# M051DN_v1 register map
File version: 1.0
Registers are 32-bit, read-write, reset 0x0 unless marked. A register's access mark holds for its fields unless they carry their own. Offsets are from the block's base; [hi:lo] are bit positions; 'fields as' and 'values as' point back to an identical list.

## TMR01 — TIMER Register Map
Base 0x40010000
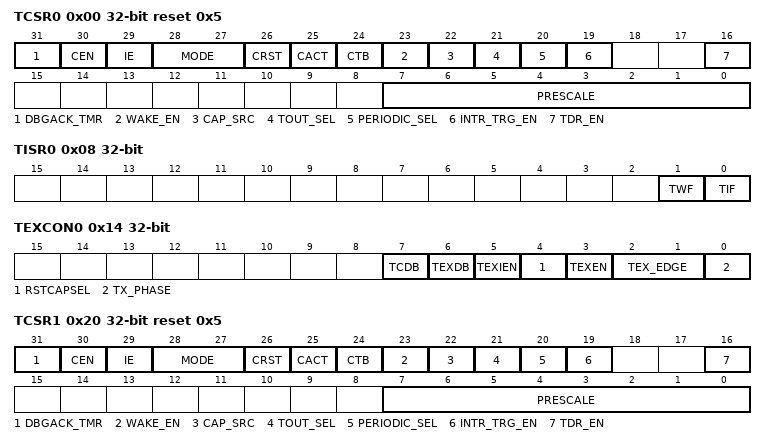
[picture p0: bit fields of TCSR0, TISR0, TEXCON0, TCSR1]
0x00 TCSR0 reset 0x5 — Timer0 Control and Status Register
  [31] DBGACK_TMR — ICE Debug Mode Acknowledge Disable (Write Protect). Timer counter will keep going no matter CPU is held by ICE or not.
    0=ICE debug mode acknowledgement effects TIMER counting; 1=ICE debug mode acknowledgement Disabled
  [30] CEN — Timer Enable Control
    0=Stops/Suspends counting; 1=Starts counting
  [29] IE — Interrupt Enable Control. If this bit is enabled, when the timer interrupt flag (TIF) is set to 1, the timer interrupt signal is generated and inform to CPU.
    0=Timer Interrupt function Disabled; 1=Timer Interrupt function Enabled
  [28:27] MODE — Timer Operating Mode
    0=The Timer controller is operated in One-shot mode; 1=The Timer controller is operated in Periodic mode; 2=The Timer controller is operated in Toggle-output mode; 3=The Timer controller is operated in Continuous Counting mode
  [26] CRST — Timer Reset
    0=No effect; 1=Reset 8-bit prescale counter, 24-bit up counter value and CEN bit if CACT is 1
  [25] CACT ro — Timer Active Status (Read Only). This bit indicates the 24-bit up counter status.
    0=24-bit up counter is not active; 1=24-bit up counter is active
  [24] CTB — Counter Mode Enable Control. This bit is for external counting pin function enabled. When timer is used as an event counter, this bit should be set to 1 and select HCLK as timer clock source. Please refer to section 6.7.5.3 for detail description.
    0=External event counter mode Disabled; 1=External event counter mode Enabled
  [23] WAKE_EN — Wake-up Function Enable Control (M05xxDN/DE Only)
    0=Wake-up trigger event Disabled; 1=Wake-up trigger event Enabled
  [22] CAP_SRC — Capture Pin Source Selection (M05xxDN/DE Only)
    0=Capture Function source is from TxEX pin; 1=Capture Function source is from internal ACMPx output signal
  [21] TOUT_SEL — Toggle-output Pin Selection (M05xxDN/DE Only)
    0=Toggle-output pin is from Tx pin; 1=Toggle-output pin is from TxEx pin
  [20] PERIODIC_SEL — Periodic Mode Behavior Selection Enable (M05xxDN/DE Only). If updated TCMP value TDR, TDR will be reset to default value.
    0=The behavior selection in periodic mode is Disabled; 1=The behavior selection in periodic mode is Enabled
  [19] INTR_TRG_EN — Inter-timer Trigger Mode Enable Control (M05xxDN/DE Only). Setting this bit will enable the inter-timer trigger capture function. The Timer0/2 will be in counter mode and counting with external clock source or event.Also, Timer1/3 will be in trigger-counting mode of capture function. Note: For Timer1/3, this bit is ignored and the read back value is always 0.
    0=Inter-Timer Trigger Capture mode Disabled; 1=Inter-Timer Trigger Capture mode Enabled
  [16] TDR_EN — Data Load Enable Control. When TDR_EN is set, TDR (Timer Data Register) will be updated continuously with the 24-bit up-timer value as the timer is counting.
    0=Timer Data Register update Disabled; 1=Timer Data Register update Enabled while Timer counter is active
  [7:0] PRESCALE — Prescale Counter
0x04 TCMPR0 — Timer0 Compare Register
  [23:0] TCMP — Timer Compared Value. TCMP is a 24-bit compared value register. When the internal 24-bit up counter value is equal to TCMP value, the TIF flag will set to 1. Note1: Never write 0x0 or 0x1 in TCMP field, or the core will run into unknown state. Note2: When Timer is operating at Continuous Counting mode, the 24-bit up counter will keep counting continuously even if software writes a new value into TCMP field. But if Timer is operating at other modes except Periodic mode on M05xxDN/DE, the 24-bit up counter will restart counting and using newest TCMP value to be the timer compared value if software writes a new value into TCMP field.
0x08 TISR0 — Timer0 Interrupt Status Register
  [1] TWF — Timer Wake-up Flag (M05xxDN/DE Only). This bit indicates the interrupt wake-up flag status of Time. Note: This bit is cleared by writing 1 to it.
    0=Timer does not cause chip wake-up; 1=Chip wake-up from Idle or Power-down mode if Timer time-out interrupt signal generated
  [0] TIF — Timer Interrupt Flag. This bit indicates the interrupt flag status of Timer while TDR value reaches to TCMP value. Note: This bit is cleared by writing 1 to it.
    0=No effect; 1=TDR value matches the TCMP value
0x0C TDR0 ro — Timer0 Data Register
  [23:0] TDR — Timer Data Register. If TDR_EN is set to 1, TDR register value will be updated continuously to monitor 24-bit up counter value.
0x10 TCAP0 ro — Timer0 Capture Data Register
  [23:0] TCAP — Timer Capture Data Register. When TEXIF flag is set to 1, the current TDR value will be auto-loaded into this TCAP filed immediately.
0x14 TEXCON0 — Timer0 External Control Register
  [7] TCDB — Timer External Counter Input Pin De-bounce Enable Control. If this bit is enabled, the edge detection of Tx pin is detected with de-bounce circuit.
    0=Tx pin de-bounce Disabled; 1=Tx pin de-bounce Enabled
  [6] TEXDB — Timer External Capture Input Pin De-bounce Enable Control. If this bit is enabled, the edge detection of TxEX pin is detected with de-bounce circuit.
    0=TxEX pin de-bounce Disabled; 1=TxEX pin de-bounce Enabled
  [5] TEXIEN — Timer External Capture Interrupt Enable Control. If TEXIEN enabled, Timer will raise an external capture interrupt signal and inform to CPU while TEXIF flag is set to 1.
    0=TxEX pin detection Interrupt Disabled; 1=TxEX pin detection Interrupt Enabled
  [4] RSTCAPSEL — Timer External Reset Counter / Timer External Capture Mode Selection
    0=Transition on TxEX pin is using to save the TDR value into TCAP value if TEXIF flag is set to 1; 1=Transition on TxEX pin is using to reset the 24-bit up counter
  [3] TEXEN — Timer External Pin Function Enable. This bit enables the RSTCAPSEL function on the TxEX pin.
    0=RSTCAPSEL function of TxEX pin will be ignored; 1=RSTCAPSEL function of TxEX pin is active
  [2:1] TEX_EDGE — Timer External Capture Pin Edge Detect Selection
    0=A 1 to 0 transition on TxEX pin will be detected; 1=A 0 to 1 transition on TxEX pin will be detected; 2=Either 1 to 0 or 0 to 1 transition on TxEX pin will be detected
  [0] TX_PHASE — Timer External Count Pin Phase Detect Selection. This bit indicates the detection phase of Tx pin.
    0=A falling edge of Tx pin will be counted; 1=A rising edge of Tx pin will be counted
0x18 TEXISR0 — Timer0 External Interrupt Status Register
  [0] TEXIF — Timer External Capture Interrupt Flag. This bit indicates the external capture interrupt flag status. When TEXEN enabled, TxEX pin selected as external capture function, and a transition on TxEX pin matched the TEX_EDGE setting, this flag will set to 1 by hardware. Note: This bit is cleared by writing 1 to it.
    0=TxEX pin interrupt did not occur; 1=TxEX pin interrupt occurred
0x20 TCSR1 reset 0x5 — Timer1 Control and Status Register
  fields as TCSR0
0x24 TCMPR1 — Timer1 Compare Register
  fields as TCMPR0
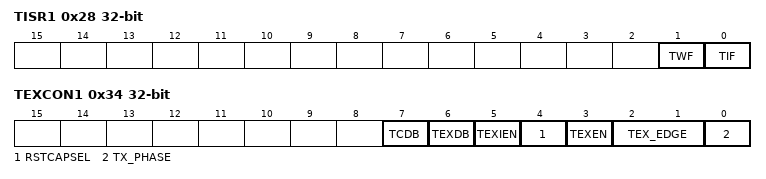
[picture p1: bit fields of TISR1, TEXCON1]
0x28 TISR1 — Timer1 Interrupt Status Register
  fields as TISR0
0x2C TDR1 ro — Timer1 Data Register
  fields as TDR0
0x30 TCAP1 ro — Timer1 Capture Data Register
  fields as TCAP0
0x34 TEXCON1 — Timer1 External Control Register
  fields as TEXCON0
0x38 TEXISR1 — Timer1 External Interrupt Status Register
  fields as TEXISR0
